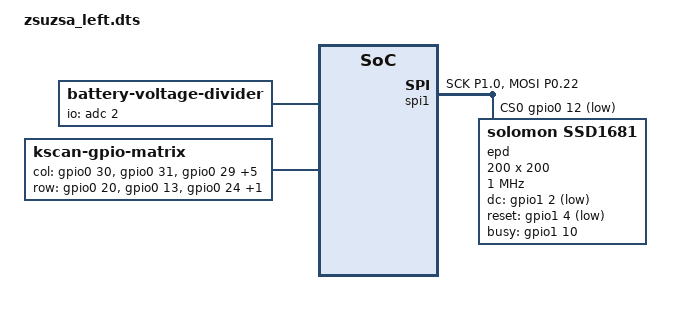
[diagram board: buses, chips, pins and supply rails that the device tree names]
/*
* Copyright (c) 2023 CTDD
* SPDX-License-Identifier: MIT
*/

#include "zsuzsa.dtsi"

/{
    chosen {
        //zephyr,display = &epd; // uncomment this for display
        zmk,battery = &vbatt;
        zephyr,display = &epd;
    };

    vbatt: vbatt {
        compatible = "zmk,battery-voltage-divider";
        label = "BATTERY";
        io-channels = <&adc 2>;
        output-ohms = <2000000>;
        full-ohms = <(2000000 + 820000)>; // 2M + 820k maybe need change
    };

    kscan0: kscan {
        compatible = "zmk,kscan-gpio-matrix";
        label = "KSCAN";

        diode-direction = "col2row";

        col-gpios
            = <&gpio0 30 GPIO_ACTIVE_HIGH>
            , <&gpio0 31 GPIO_ACTIVE_HIGH>
            , <&gpio0 29 GPIO_ACTIVE_HIGH>
            , <&gpio0 2 GPIO_ACTIVE_HIGH>
            , <&gpio1 13 GPIO_ACTIVE_HIGH>
            , <&gpio0 28 GPIO_ACTIVE_HIGH>
            , <&gpio0 3 GPIO_ACTIVE_HIGH>
            , <&gpio1 11 GPIO_ACTIVE_HIGH>
            ;

        row-gpios
            = <&gpio0 20 (GPIO_ACTIVE_HIGH | GPIO_PULL_DOWN)>
            , <&gpio0 13 (GPIO_ACTIVE_HIGH | GPIO_PULL_DOWN)>
            , <&gpio0 24 (GPIO_ACTIVE_HIGH | GPIO_PULL_DOWN)>
            , <&gpio0 9 (GPIO_ACTIVE_HIGH | GPIO_PULL_DOWN)>
            ;
    };
};

// TODO: edit for e-ink and spi

&pinctrl {
    spi2_default: spi2_default {
        group1 {
            psels = <NRF_PSEL(SPIM_SCK, 1, 0)>,
                <NRF_PSEL(SPIM_MOSI, 0, 22)>,
                <NRF_PSEL_DISCONNECTED(SPIM_MISO)>;
        };
    };

    spi2_sleep: spi2_sleep {
        group1 {
            psels = <NRF_PSEL(SPIM_SCK, 1, 1)>,
                <NRF_PSEL(SPIM_MOSI, 0, 22)>,
                <NRF_PSEL_DISCONNECTED(SPIM_MISO)>;
                
            low-power-enable;
        };
    };
}; // maybe need gpio for CE, not sure, test it x2
// need more gpio for BUSY, RST, not sure how to add yet

// edit this
&spi1 {
    status = "okay";
    compatible = "nordic,nrf-spim";
    pinctrl-0 = <&spi2_default>;
    pinctrl-1 = <&spi2_sleep>;
    pinctrl-names = "default", "sleep";
    cs-gpios = <&gpio0 12 GPIO_ACTIVE_LOW>;

    epd: display@0 {
        compatible = "solomon,ssd1681";
        reg        = <0>;                      /* SPI CS line 0 */
        width      = <200>;
        height     = <200>;
        dc-gpios   = <&gpio1 2  GPIO_ACTIVE_LOW>;   /* D/C pin */
        reset-gpios= <&gpio1 4  GPIO_ACTIVE_LOW>;   /* RST pin */
        busy-gpios = <&gpio1 10 GPIO_ACTIVE_HIGH>;  /* BUSY pin */
        spi-max-frequency = <1000000>;          /* Reduced for stability */
    };
};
